# C6424_cslr_edmacc register map
Vendor: Texas Instruments
Peripheral module from a debugger description file.
Registers are 32-bit, read-write, reset 0x0 unless marked. A register's access mark holds for its fields unless they carry their own. Offsets are as the file gives them; lines under a group give offsets from that group; [hi:lo] are bit positions; {n}, {i} and the like mark numbered series; 'fields as' and 'values as' point back to an identical list; <NAME> marks a mode.

## EDMACC — Enhanced DMA Channel Controller Module.
0x00 REV ro reset 0x40015300 — Peripheral Revision
  [31:0] PID — Reserved
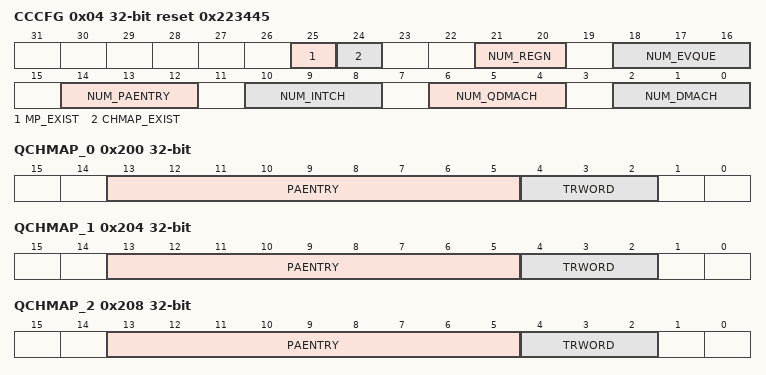
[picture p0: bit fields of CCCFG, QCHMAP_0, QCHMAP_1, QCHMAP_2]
0x04 CCCFG access not given reset 0x223445 — CC Configuration
  [25] MP_EXIST ro — Memory Protection Existence
    0=None (No Memory protection); 1=INCLUDED (Memory protection logic included)
  [24] CHMAP_EXIST ro — Channel Mapping Existence
    0=None (No Channel Mapping); 1=INCLUDED (Channel mapping logic included)
  [21:20] NUM_REGN ro — Number of MP and Shadow regions
    0=0 Regions; 1=2 Regions; 2=4 Regions; 3=8 Regions
  [18:16] NUM_EVQUE ro — Number of Queues/Number of TCs
    {v}={v+1} TC/Event Queue (v=0..7)
  [14:12] NUM_PAENTRY ro — Number of PaRAM entries
    0=16 Entries; 1=32 Entries; 2=64 Entries; 3=128 Entries; 4=256 Entries; 5=512 Entries
  [10:8] NUM_INTCH ro — Number of Interrupt Channels
    1=8 Interrupt Channels; 2=16 Interrupt Channels; 3=32 Interrupt Channels; 4=64 Interrupt Channels
  [6:4] NUM_QDMACH ro — Number of QDMA Channels
    0=NONE (No QDMA Channels); 1=2 QDMA Channels; 2=4 QDMA Channels; 3=6 QDMA Channels; 4=8 QDMA Channels
  [2:0] NUM_DMACH ro — Number of DMA Channels
    0=NONE (No DMA Channels); 1=4 DMA Channels; 2=8 DMA Channels; 3=16 DMA Channels; 4=32 DMA Channels; 5=64 DMA Channels
0x200 QCHMAP_0 access not given — QDMA Channel Mapping to PaRAM{QCHMAP}
  [13:5] PAENTRY rw — Points to the PaRAM Entry number for the DMA Channel N
  [4:2] TRWORD rw — Points to the specific trigger word of the PaRAM entry defined by PAENTRY
0x204 QCHMAP_1 access not given — QDMA Channel Mapping to PaRAM{QCHMAP}
  fields as QCHMAP_0
0x208 QCHMAP_2 access not given — QDMA Channel Mapping to PaRAM{QCHMAP}
  fields as QCHMAP_0
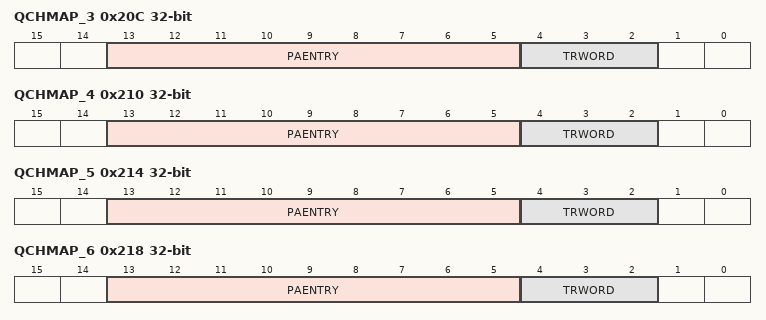
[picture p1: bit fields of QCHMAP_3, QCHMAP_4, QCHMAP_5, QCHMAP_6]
0x20C QCHMAP_3 access not given — QDMA Channel Mapping to PaRAM{QCHMAP}
  fields as QCHMAP_0
0x210 QCHMAP_4 access not given — QDMA Channel Mapping to PaRAM{QCHMAP}
  fields as QCHMAP_0
0x214 QCHMAP_5 access not given — QDMA Channel Mapping to PaRAM{QCHMAP}
  fields as QCHMAP_0
0x218 QCHMAP_6 access not given — QDMA Channel Mapping to PaRAM{QCHMAP}
  fields as QCHMAP_0
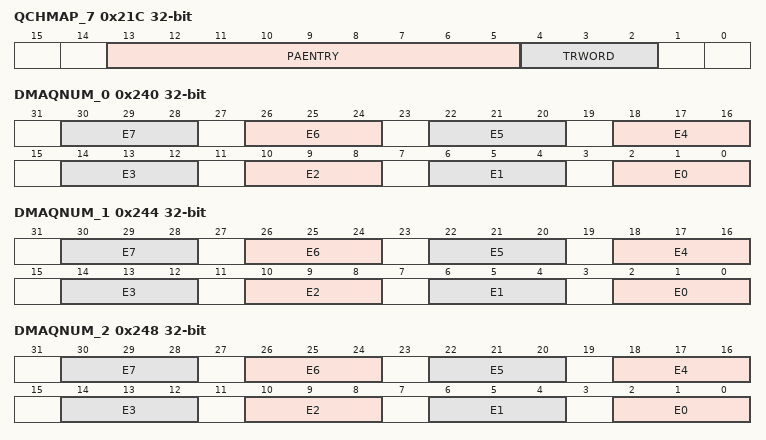
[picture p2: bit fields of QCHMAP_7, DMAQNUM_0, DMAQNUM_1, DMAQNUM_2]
0x21C QCHMAP_7 access not given — QDMA Channel Mapping to PaRAM{QCHMAP}
  fields as QCHMAP_0
0x240 DMAQNUM_0 access not given — DMA Queue Number{DMAQNUM}
  [4n+2:4n] E{n} rw (n=0..7) — Event number = (ArrayIndex * 8) + {n}
0x244 DMAQNUM_1 access not given — DMA Queue Number{DMAQNUM}
  [4n+2:4n] E{n} rw (n=0..7) — Event number = (ArrayIndex * 8) + {n}
0x248 DMAQNUM_2 access not given — DMA Queue Number{DMAQNUM}
  [4n+2:4n] E{n} rw (n=0..7) — Event number = (ArrayIndex * 8) + {n}
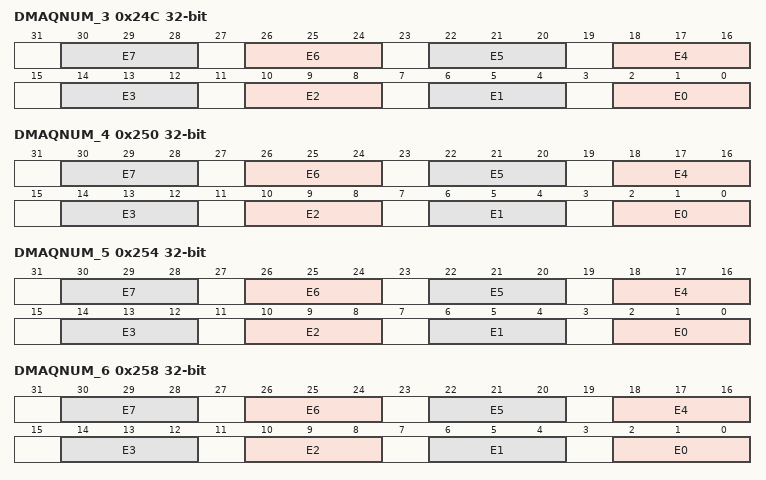
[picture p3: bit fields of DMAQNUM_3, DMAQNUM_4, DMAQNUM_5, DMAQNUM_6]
0x24C DMAQNUM_3 access not given — DMA Queue Number{DMAQNUM}
  [4n+2:4n] E{n} rw (n=0..7) — Event number = (ArrayIndex * 8) + {n}
0x250 DMAQNUM_4 access not given — DMA Queue Number{DMAQNUM}
  [4n+2:4n] E{n} rw (n=0..7) — Event number = (ArrayIndex * 8) + {n}
0x254 DMAQNUM_5 access not given — DMA Queue Number{DMAQNUM}
  [4n+2:4n] E{n} rw (n=0..7) — Event number = (ArrayIndex * 8) + {n}
0x258 DMAQNUM_6 access not given — DMA Queue Number{DMAQNUM}
  [4n+2:4n] E{n} rw (n=0..7) — Event number = (ArrayIndex * 8) + {n}
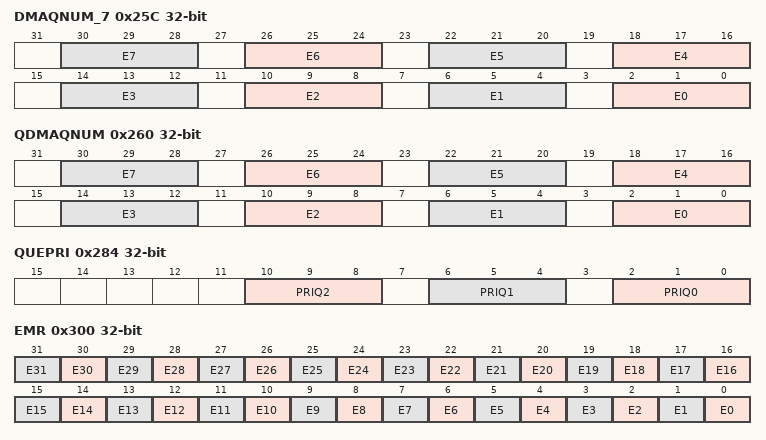
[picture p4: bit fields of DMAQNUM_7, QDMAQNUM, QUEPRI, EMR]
0x25C DMAQNUM_7 access not given — DMA Queue Number{DMAQNUM}
  [4n+2:4n] E{n} rw (n=0..7) — Event number = (ArrayIndex * 8) + {n}
0x260 QDMAQNUM access not given — QDMA Queue Number
  [4n+2:4n] E{n} rw (n=0..7) — Event number {n}
0x284 QUEPRI access not given — Queue Priority
  [10:8] PRIQ2 rw — Priority level for Queue 2
  [6:4] PRIQ1 rw — Priority level for Queue 1
  [2:0] PRIQ0 rw — Priority level for Queue 0
0x300 EMR ro — Event Miss Register
  [n] E{n} (n=0..31) — Event missed number {n}
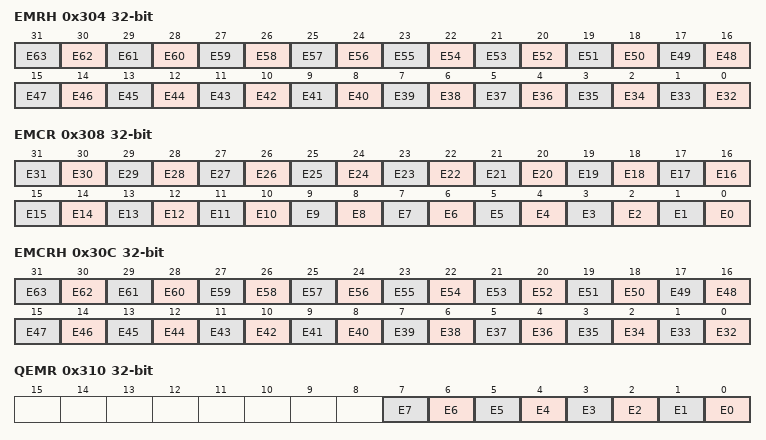
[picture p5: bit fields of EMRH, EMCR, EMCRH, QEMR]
0x304 EMRH ro — Event Miss Register High
  [n-32] E{n} (n=32..63) — Event missed number {n}
0x308 EMCR ro — Event Miss Clear Register
  [n] E{n} (n=0..31) — Event missed number {n}
0x30C EMCRH ro — Event Miss Clear Register High
  [n-32] E{n} (n=32..63) — Event missed number {n}
0x310 QEMR access not given — QDMA Event Miss Register
  [n] E{n} ro (n=0..7) — Event miss event {n}
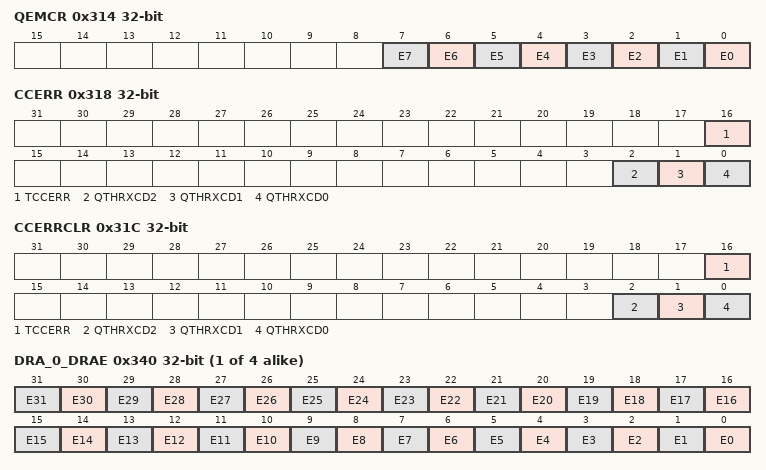
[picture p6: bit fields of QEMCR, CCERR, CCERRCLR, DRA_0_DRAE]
0x314 QEMCR access not given — QDMA Event Miss Register
  [n] E{n} wo (n=0..7) — Event miss event {n}
0x318 CCERR access not given — CC Error Register
  [16] TCCERR ro — Transfer completion code error
  [2] QTHRXCD2 ro — Queue Threshold Error for Queue 2
  [1] QTHRXCD1 ro — Queue Threshold Error for Queue 1
  [0] QTHRXCD0 ro — Queue Threshold Error for Queue 0
0x31C CCERRCLR access not given — CC Error Clear Register
  [16] TCCERR wo — Transfer completion code error
  [2] QTHRXCD2 wo — Queue Threshold Error for Queue 2
  [1] QTHRXCD1 wo — Queue Threshold Error for Queue 1
  [0] QTHRXCD0 wo — Queue Threshold Error for Queue 0
0x320 EEVAL access not given — Error Evaluation Register
  [0] EVAL wo — Error interrupt Evaluate
    1=EVAL (Error Interrupt Evaluate)
{0x340+8i} DRA_{i}_DRAE ro (i=0..3) — DMA Region Access Enable
  [n] E{n} (n=0..31) — Event missed number {n}
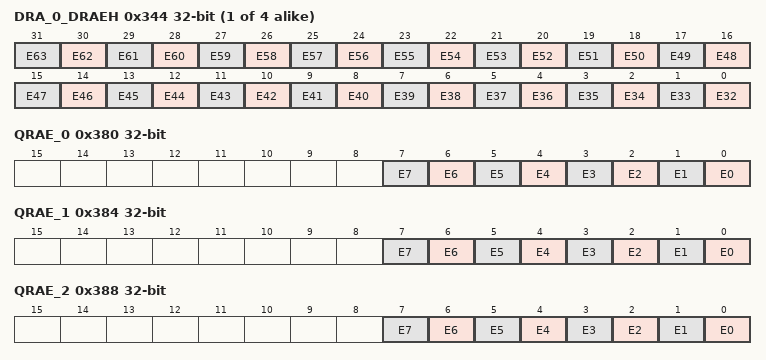
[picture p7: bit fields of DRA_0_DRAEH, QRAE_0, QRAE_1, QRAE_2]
{0x344+8i} DRA_{i}_DRAEH ro (i=0..3) — DMA Region Access Enable High
  [n-32] E{n} (n=32..63) — Event missed number {n}
0x380 QRAE_0 access not given — QDMA Region Access Enable{QRAE}
  [n] E{n} ro (n=0..7) — QDMA Register bit {n}
0x384 QRAE_1 access not given — QDMA Region Access Enable{QRAE}
  [n] E{n} ro (n=0..7) — QDMA Register bit {n}
0x388 QRAE_2 access not given — QDMA Region Access Enable{QRAE}
  [n] E{n} ro (n=0..7) — QDMA Register bit {n}
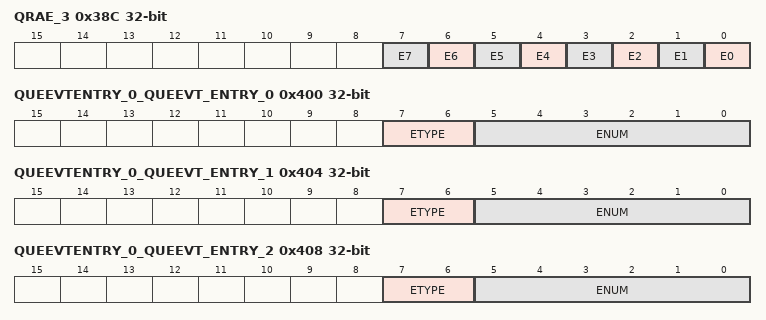
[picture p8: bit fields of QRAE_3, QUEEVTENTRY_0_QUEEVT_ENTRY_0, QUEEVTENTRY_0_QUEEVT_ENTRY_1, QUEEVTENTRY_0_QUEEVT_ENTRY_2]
0x38C QRAE_3 access not given — QDMA Region Access Enable{QRAE}
  [n] E{n} ro (n=0..7) — QDMA Register bit {n}
0x400 QUEEVTENTRY_0_QUEEVT_ENTRY_0 ro — Event Entry{EVT_ENTRY}
  [7:6] ETYPE — Event Source - ER/ESR/CER/QER
  [5:0] ENUM — Event
0x404 QUEEVTENTRY_0_QUEEVT_ENTRY_1 ro — Event Entry{EVT_ENTRY}
  [7:6] ETYPE — Event Source - ER/ESR/CER/QER
  [5:0] ENUM — Event
0x408 QUEEVTENTRY_0_QUEEVT_ENTRY_2 ro — Event Entry{EVT_ENTRY}
  [7:6] ETYPE — Event Source - ER/ESR/CER/QER
  [5:0] ENUM — Event
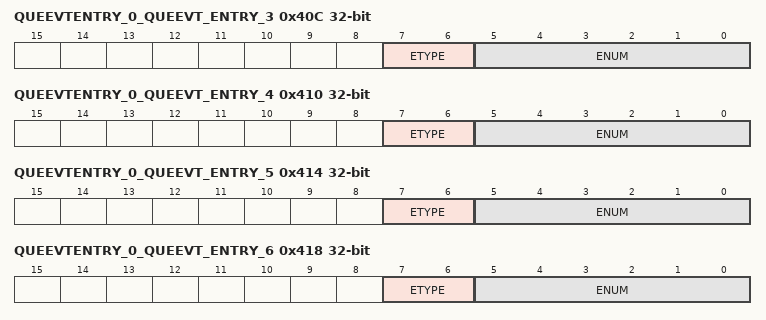
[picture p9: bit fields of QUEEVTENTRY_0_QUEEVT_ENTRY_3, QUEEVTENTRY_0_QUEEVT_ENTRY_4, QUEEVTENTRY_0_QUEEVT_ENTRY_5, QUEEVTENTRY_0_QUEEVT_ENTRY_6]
0x40C QUEEVTENTRY_0_QUEEVT_ENTRY_3 ro — Event Entry{EVT_ENTRY}
  [7:6] ETYPE — Event Source - ER/ESR/CER/QER
  [5:0] ENUM — Event
0x410 QUEEVTENTRY_0_QUEEVT_ENTRY_4 ro — Event Entry{EVT_ENTRY}
  [7:6] ETYPE — Event Source - ER/ESR/CER/QER
  [5:0] ENUM — Event
0x414 QUEEVTENTRY_0_QUEEVT_ENTRY_5 ro — Event Entry{EVT_ENTRY}
  [7:6] ETYPE — Event Source - ER/ESR/CER/QER
  [5:0] ENUM — Event
0x418 QUEEVTENTRY_0_QUEEVT_ENTRY_6 ro — Event Entry{EVT_ENTRY}
  [7:6] ETYPE — Event Source - ER/ESR/CER/QER
  [5:0] ENUM — Event
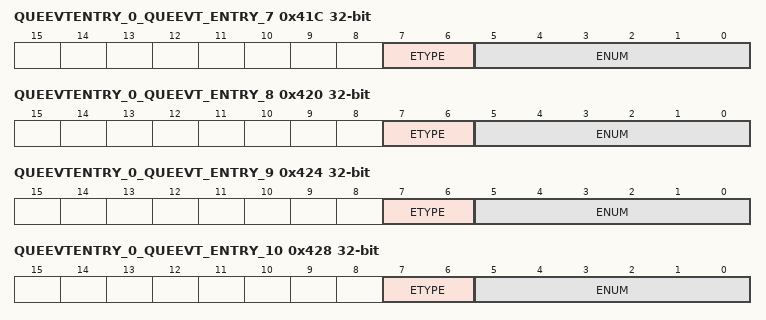
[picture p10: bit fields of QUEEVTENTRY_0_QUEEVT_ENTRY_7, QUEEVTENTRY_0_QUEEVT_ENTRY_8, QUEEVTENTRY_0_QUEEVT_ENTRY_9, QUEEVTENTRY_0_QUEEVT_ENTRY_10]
0x41C QUEEVTENTRY_0_QUEEVT_ENTRY_7 ro — Event Entry{EVT_ENTRY}
  [7:6] ETYPE — Event Source - ER/ESR/CER/QER
  [5:0] ENUM — Event
0x420 QUEEVTENTRY_0_QUEEVT_ENTRY_8 ro — Event Entry{EVT_ENTRY}
  [7:6] ETYPE — Event Source - ER/ESR/CER/QER
  [5:0] ENUM — Event
0x424 QUEEVTENTRY_0_QUEEVT_ENTRY_9 ro — Event Entry{EVT_ENTRY}
  [7:6] ETYPE — Event Source - ER/ESR/CER/QER
  [5:0] ENUM — Event
0x428 QUEEVTENTRY_0_QUEEVT_ENTRY_10 ro — Event Entry{EVT_ENTRY}
  [7:6] ETYPE — Event Source - ER/ESR/CER/QER
  [5:0] ENUM — Event
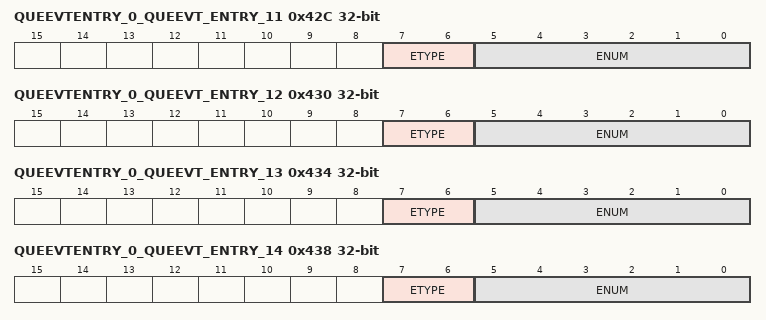
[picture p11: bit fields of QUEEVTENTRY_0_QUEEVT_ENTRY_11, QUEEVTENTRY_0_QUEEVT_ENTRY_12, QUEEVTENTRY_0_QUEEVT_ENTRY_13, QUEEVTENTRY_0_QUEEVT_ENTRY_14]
0x42C QUEEVTENTRY_0_QUEEVT_ENTRY_11 ro — Event Entry{EVT_ENTRY}
  [7:6] ETYPE — Event Source - ER/ESR/CER/QER
  [5:0] ENUM — Event
0x430 QUEEVTENTRY_0_QUEEVT_ENTRY_12 ro — Event Entry{EVT_ENTRY}
  [7:6] ETYPE — Event Source - ER/ESR/CER/QER
  [5:0] ENUM — Event
0x434 QUEEVTENTRY_0_QUEEVT_ENTRY_13 ro — Event Entry{EVT_ENTRY}
  [7:6] ETYPE — Event Source - ER/ESR/CER/QER
  [5:0] ENUM — Event
0x438 QUEEVTENTRY_0_QUEEVT_ENTRY_14 ro — Event Entry{EVT_ENTRY}
  [7:6] ETYPE — Event Source - ER/ESR/CER/QER
  [5:0] ENUM — Event
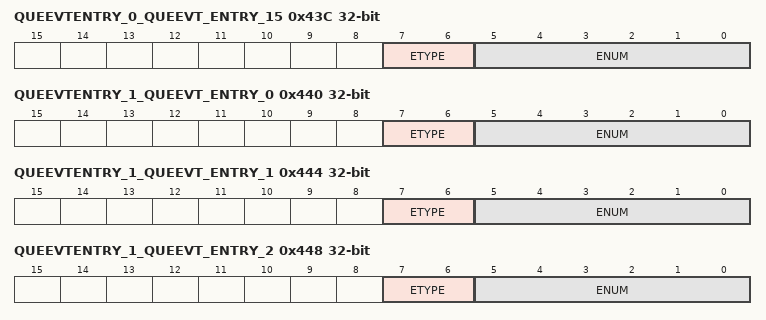
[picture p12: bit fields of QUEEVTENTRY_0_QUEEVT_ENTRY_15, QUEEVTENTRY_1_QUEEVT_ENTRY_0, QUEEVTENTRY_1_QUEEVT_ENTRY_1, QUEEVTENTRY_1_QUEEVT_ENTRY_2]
0x43C QUEEVTENTRY_0_QUEEVT_ENTRY_15 ro — Event Entry{EVT_ENTRY}
  [7:6] ETYPE — Event Source - ER/ESR/CER/QER
  [5:0] ENUM — Event
0x440 QUEEVTENTRY_1_QUEEVT_ENTRY_0 ro — Event Entry{EVT_ENTRY}
  [7:6] ETYPE — Event Source - ER/ESR/CER/QER
  [5:0] ENUM — Event
0x444 QUEEVTENTRY_1_QUEEVT_ENTRY_1 ro — Event Entry{EVT_ENTRY}
  [7:6] ETYPE — Event Source - ER/ESR/CER/QER
  [5:0] ENUM — Event
0x448 QUEEVTENTRY_1_QUEEVT_ENTRY_2 ro — Event Entry{EVT_ENTRY}
  [7:6] ETYPE — Event Source - ER/ESR/CER/QER
  [5:0] ENUM — Event
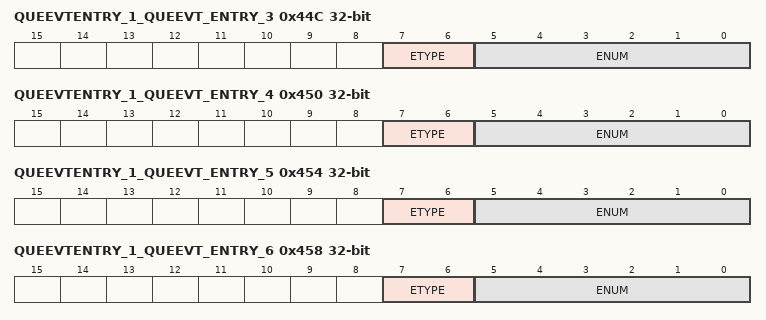
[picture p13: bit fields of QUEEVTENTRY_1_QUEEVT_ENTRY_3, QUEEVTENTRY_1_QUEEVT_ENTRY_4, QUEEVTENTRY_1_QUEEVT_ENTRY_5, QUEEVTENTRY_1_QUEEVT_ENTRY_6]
0x44C QUEEVTENTRY_1_QUEEVT_ENTRY_3 ro — Event Entry{EVT_ENTRY}
  [7:6] ETYPE — Event Source - ER/ESR/CER/QER
  [5:0] ENUM — Event
0x450 QUEEVTENTRY_1_QUEEVT_ENTRY_4 ro — Event Entry{EVT_ENTRY}
  [7:6] ETYPE — Event Source - ER/ESR/CER/QER
  [5:0] ENUM — Event
0x454 QUEEVTENTRY_1_QUEEVT_ENTRY_5 ro — Event Entry{EVT_ENTRY}
  [7:6] ETYPE — Event Source - ER/ESR/CER/QER
  [5:0] ENUM — Event
0x458 QUEEVTENTRY_1_QUEEVT_ENTRY_6 ro — Event Entry{EVT_ENTRY}
  [7:6] ETYPE — Event Source - ER/ESR/CER/QER
  [5:0] ENUM — Event
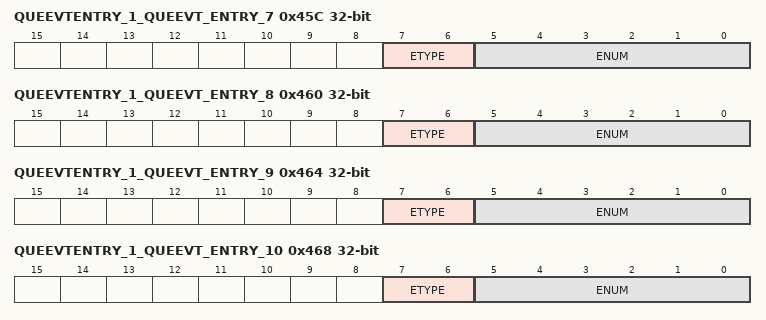
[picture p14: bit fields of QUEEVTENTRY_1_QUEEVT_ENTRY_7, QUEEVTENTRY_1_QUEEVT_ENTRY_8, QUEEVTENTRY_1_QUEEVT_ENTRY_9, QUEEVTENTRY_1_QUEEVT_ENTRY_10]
0x45C QUEEVTENTRY_1_QUEEVT_ENTRY_7 ro — Event Entry{EVT_ENTRY}
  [7:6] ETYPE — Event Source - ER/ESR/CER/QER
  [5:0] ENUM — Event
0x460 QUEEVTENTRY_1_QUEEVT_ENTRY_8 ro — Event Entry{EVT_ENTRY}
  [7:6] ETYPE — Event Source - ER/ESR/CER/QER
  [5:0] ENUM — Event
0x464 QUEEVTENTRY_1_QUEEVT_ENTRY_9 ro — Event Entry{EVT_ENTRY}
  [7:6] ETYPE — Event Source - ER/ESR/CER/QER
  [5:0] ENUM — Event
0x468 QUEEVTENTRY_1_QUEEVT_ENTRY_10 ro — Event Entry{EVT_ENTRY}
  [7:6] ETYPE — Event Source - ER/ESR/CER/QER
  [5:0] ENUM — Event
0x46C QUEEVTENTRY_1_QUEEVT_ENTRY_11 ro — Event Entry{EVT_ENTRY}
  [7:6] ETYPE — Event Source - ER/ESR/CER/QER
  [5:0] ENUM — Event
0x470 QUEEVTENTRY_1_QUEEVT_ENTRY_12 ro — Event Entry{EVT_ENTRY}
  [7:6] ETYPE — Event Source - ER/ESR/CER/QER
  [5:0] ENUM — Event
0x474 QUEEVTENTRY_1_QUEEVT_ENTRY_13 ro — Event Entry{EVT_ENTRY}
  [7:6] ETYPE — Event Source - ER/ESR/CER/QER
  [5:0] ENUM — Event
0x478 QUEEVTENTRY_1_QUEEVT_ENTRY_14 ro — Event Entry{EVT_ENTRY}
  [7:6] ETYPE — Event Source - ER/ESR/CER/QER
  [5:0] ENUM — Event
0x47C QUEEVTENTRY_1_QUEEVT_ENTRY_15 ro — Event Entry{EVT_ENTRY}
  [7:6] ETYPE — Event Source - ER/ESR/CER/QER
  [5:0] ENUM — Event
0x480 QUEEVTENTRY_2_QUEEVT_ENTRY_0 ro — Event Entry{EVT_ENTRY}
  [7:6] ETYPE — Event Source - ER/ESR/CER/QER
  [5:0] ENUM — Event
0x484 QUEEVTENTRY_2_QUEEVT_ENTRY_1 ro — Event Entry{EVT_ENTRY}
  [7:6] ETYPE — Event Source - ER/ESR/CER/QER
  [5:0] ENUM — Event
0x488 QUEEVTENTRY_2_QUEEVT_ENTRY_2 ro — Event Entry{EVT_ENTRY}
  [7:6] ETYPE — Event Source - ER/ESR/CER/QER
  [5:0] ENUM — Event
0x48C QUEEVTENTRY_2_QUEEVT_ENTRY_3 ro — Event Entry{EVT_ENTRY}
  [7:6] ETYPE — Event Source - ER/ESR/CER/QER
  [5:0] ENUM — Event
0x490 QUEEVTENTRY_2_QUEEVT_ENTRY_4 ro — Event Entry{EVT_ENTRY}
  [7:6] ETYPE — Event Source - ER/ESR/CER/QER
  [5:0] ENUM — Event
0x494 QUEEVTENTRY_2_QUEEVT_ENTRY_5 ro — Event Entry{EVT_ENTRY}
  [7:6] ETYPE — Event Source - ER/ESR/CER/QER
  [5:0] ENUM — Event
0x498 QUEEVTENTRY_2_QUEEVT_ENTRY_6 ro — Event Entry{EVT_ENTRY}
  [7:6] ETYPE — Event Source - ER/ESR/CER/QER
  [5:0] ENUM — Event
0x49C QUEEVTENTRY_2_QUEEVT_ENTRY_7 ro — Event Entry{EVT_ENTRY}
  [7:6] ETYPE — Event Source - ER/ESR/CER/QER
  [5:0] ENUM — Event
0x4A0 QUEEVTENTRY_2_QUEEVT_ENTRY_8 ro — Event Entry{EVT_ENTRY}
  [7:6] ETYPE — Event Source - ER/ESR/CER/QER
  [5:0] ENUM — Event
0x4A4 QUEEVTENTRY_2_QUEEVT_ENTRY_9 ro — Event Entry{EVT_ENTRY}
  [7:6] ETYPE — Event Source - ER/ESR/CER/QER
  [5:0] ENUM — Event
0x4A8 QUEEVTENTRY_2_QUEEVT_ENTRY_10 ro — Event Entry{EVT_ENTRY}
  [7:6] ETYPE — Event Source - ER/ESR/CER/QER
  [5:0] ENUM — Event
0x4AC QUEEVTENTRY_2_QUEEVT_ENTRY_11 ro — Event Entry{EVT_ENTRY}
  [7:6] ETYPE — Event Source - ER/ESR/CER/QER
  [5:0] ENUM — Event
0x4B0 QUEEVTENTRY_2_QUEEVT_ENTRY_12 ro — Event Entry{EVT_ENTRY}
  [7:6] ETYPE — Event Source - ER/ESR/CER/QER
  [5:0] ENUM — Event
0x4B4 QUEEVTENTRY_2_QUEEVT_ENTRY_13 ro — Event Entry{EVT_ENTRY}
  [7:6] ETYPE — Event Source - ER/ESR/CER/QER
  [5:0] ENUM — Event
0x4B8 QUEEVTENTRY_2_QUEEVT_ENTRY_14 ro — Event Entry{EVT_ENTRY}
  [7:6] ETYPE — Event Source - ER/ESR/CER/QER
  [5:0] ENUM — Event
0x4BC QUEEVTENTRY_2_QUEEVT_ENTRY_15 ro — Event Entry{EVT_ENTRY}
  [7:6] ETYPE — Event Source - ER/ESR/CER/QER
  [5:0] ENUM — Event
0x600 QSTAT_0 access not given — Queue Status{QSTAT}
  [24] THRXD ro — Threshold Exceeded
  [22:21] Reserved — (access N)
  [20:16] WM ro — Watermark for Maximum Queue Usage
  [12:8] NUMVAL ro — Number of Valid Entries in Queue
  [3:0] STRTPTR ro — Start Pointer
0x604 QSTAT_1 access not given — Queue Status{QSTAT}
  fields as QSTAT_0
0x608 QSTAT_2 access not given — Queue Status{QSTAT}
  fields as QSTAT_0
0x620 QWMTHRA access not given reset 0x101010 — Queue Threshold A
  [20:16] Q2 rw — Q2 Threshold
  [12:8] Q1 rw — Q1 Threshold
  [4:0] Q0 rw — Q0 Threshold
0x640 CCSTAT access not given — Channel Controller Status
  [18] QUEACTV2 ro — Queue 2 Active
    0=NONE; 1=ACTIVE
  [17] QUEACTV1 ro — Queue 1 Active
    0=NONE; 1=ACTIVE
  [16] QUEACTV0 ro — Queue 0 Active
    0=NONE; 1=ACTIVE
  [13:8] COMPACT ro — Completion Request Active
    0=NONE
  [7:5] _RESV_7 — (access N)
  [4] ACTV ro — Channel Controller Active
    0=IDLE; 1=BUSY
  [3] _RESV_9 — (access N)
  [2] TRACTV ro — Transfer Request Active
    0=NONE; 1=ACTIVE
  [1] QEVTACTV ro — QDMA Event Active
    0=NONE; 1=ACTIVE
  [0] EVTACTV ro — DMA Event Active
    0=NONE; 1=ACTIVE
0x1000 ER ro — Event Register
  [n] E{n} (n=0..31) — Event {n}
0x1004 ERH ro — Event Register High
  [n-32] E{n} (n=32..63) — Event {n}
0x1008 ECR wo — Event Clear Register
  [all] fields
    1=CLEAR
  [n] E{n} (n=0..31) — Event {n}
0x100C ECRH wo — Event Clear Register High
  [all] fields
    1=CLEAR
  [n-32] E{n} (n=32..63) — Event {n}
0x1010 ESR wo — Event Set Register
  [all] fields
    1=SET
  [n] E{n} (n=0..31) — Event {n}
0x1014 ESRH wo — Event Set Register High
  [all] fields
    1=SET
  [n-32] E{n} (n=32..63) — Event {n}
0x1018 CER ro — Chained Event Register
  [n] E{n} (n=0..31) — Event {n}
0x101C CERH ro — Chained Event Register High
  [n-32] E{n} (n=32..63) — Event {n}
0x1020 EER ro — Event Enable Register
  [31] E31 — Event 31
    1=?
  [n] E{n} (n=0..30) — Event {n}
0x1024 EERH ro — Event Enable Register High
  [n-32] E{n} (n=32..63) — Event {n}
0x1028 EECR wo — Event Enable Clear Register
  [all] fields
    1=CLEAR
  [n] E{n} (n=0..31) — Event {n}
0x102C EECRH wo — Event Enable Clear Register High
  [all] fields
    1=CLEAR
  [n-32] E{n} (n=32..63) — Event {n}
0x1030 EESR wo — Event Enable Set Register
  [all] fields
    1=SET
  [n] E{n} (n=0..31) — Event {n}
0x1034 EESRH wo — Event Enable Set Register High
  [all] fields
    1=SET
  [n-32] E{n} (n=32..63) — Event {n}
0x1038 SER ro — Secondary Event Register
  [n] E{n} (n=0..31) — Event {n}
0x103C SERH ro — Secondary Event Register High
  [n-32] E{n} (n=32..63) — Event {n}
0x1040 SECR wo — Secondary Event Clear Register
  [all] fields
    1=CLEAR
  [n] E{n} (n=0..31) — Event {n}
0x1044 SECRH wo — Secondary Event Clear Register High
  [all] fields
    1=CLEAR
  [n-32] E{n} (n=32..63) — Event {n}
0x1050 IER ro — Interrupt Enable Register
  [n] I{n} (n=0..31) — Interrupt {n}
0x1054 IERH ro — Interrupt Enable Register High
  [n-32] I{n} (n=32..63) — Interrupt {n}
0x1058 IECR wo — Interrupt Enable Clear Register
  [all] fields
    1=CLEAR
  [n] I{n} (n=0..31) — Interrupt {n}
0x105C IECRH wo — Interrupt Enable Clear Register High
  [all] fields
    1=CLEAR
  [n-32] I{n} (n=32..63) — Interrupt {n}
0x1060 IESR wo — Interrupt Enable Set Register
  [all] fields
    1=SET
  [n] I{n} (n=0..31) — Interrupt {n}
0x1064 IESRH wo — Interrupt Enable Set Register High
  [all] fields
    1=SET
  [n-32] I{n} (n=32..63) — Interrupt {n}
0x1068 IPR ro — Interrupt Pending Register
  [n] I{n} (n=0..31) — Interrupt {n}
0x106C IPRH ro — Interrupt Pending Register High
  [n-32] I{n} (n=32..63) — Interrupt {n}
0x1070 ICR wo — Interrupt Clear Register
  [all] fields
    1=CLEAR
  [n] I{n} (n=0..31) — Interrupt {n}
0x1074 ICRH wo — Interrupt Clear Register High
  [all] fields
    1=CLEAR
  [n-32] I{n} (n=32..63) — Interrupt {n}
0x1078 IEVAL access not given — Interrupt Clear Register High
  [0] EVAL wo — Interrupt Evaluate
    1=EVAL (Causes tpcc_intN output to be pulsed is any enabled IERn and IPRn pending)
0x1080 QER access not given — QDMA Event Register
  [n] E{n} ro (n=0..7) — Event {n}
0x1084 QEER access not given — QDMA Event Enable Register
  [n] E{n} ro (n=0..7) — Event {n}
0x1088 QEECR access not given — QDMA Event Enable Clear Register
  [all] fields
    1=CLEAR
  [n] E{n} ro (n=0..7) — Event {n}
0x108C QEESR access not given — QDMA Event Enable Set Register
  [all] fields
    1=SET
  [n] E{n} ro (n=0..7) — Event {n}
0x1090 QSER access not given — QDMA Secondary Event Register
  [n] E{n} ro (n=0..7) — Event {n}
0x1094 QSECR access not given — QDMA Secondary Event Clear Register
  [all] fields
    1=CLEAR
  [n] E{n} ro (n=0..7) — Event {n}
{0x2000+0x200*i} SHADOW_{i}_ER access not given (i=0..3) — Event Register
  [31:0] REG
{0x2004+0x200*i} SHADOW_{i}_ERH access not given (i=0..3) — Event Register High
  [31:0] REG
{0x2008+0x200*i} SHADOW_{i}_ECR access not given (i=0..3) — Event Clear Register
  [31:0] REG
{0x200C+0x200*i} SHADOW_{i}_ECRH access not given (i=0..3) — Event Clear Register High
  [31:0] REG
{0x2010+0x200*i} SHADOW_{i}_ESR access not given (i=0..3) — Event Set Register
  [31:0] REG
{0x2014+0x200*i} SHADOW_{i}_ESRH access not given (i=0..3) — Event Set Register High
  [31:0] REG
{0x2018+0x200*i} SHADOW_{i}_CER access not given (i=0..3) — Chained Event Register
  [31:0] REG
{0x201C+0x200*i} SHADOW_{i}_CERH access not given (i=0..3) — Chained Event Register High
  [31:0] REG
{0x2020+0x200*i} SHADOW_{i}_EER access not given (i=0..3) — Event Enable Register
  [31:0] REG
{0x2024+0x200*i} SHADOW_{i}_EERH access not given (i=0..3) — Event Enable Register High
  [31:0] REG
{0x2028+0x200*i} SHADOW_{i}_EECR access not given (i=0..3) — Event Enable Clear Register
  [31:0] REG
{0x202C+0x200*i} SHADOW_{i}_EECRH access not given (i=0..3) — Event Enable Clear Register High
  [31:0] REG
{0x2030+0x200*i} SHADOW_{i}_EESR access not given (i=0..3) — Event Enable Set Register
  [31:0] REG
{0x2034+0x200*i} SHADOW_{i}_EESRH access not given (i=0..3) — Event Enable Set Register High
  [31:0] REG
{0x2038+0x200*i} SHADOW_{i}_SER access not given (i=0..3) — Secondary Event Register
  [31:0] REG
{0x203C+0x200*i} SHADOW_{i}_SERH access not given (i=0..3) — Secondary Event Register High
  [31:0] REG
{0x2040+0x200*i} SHADOW_{i}_SECR access not given (i=0..3) — Secondary Event Clear Register
  [31:0] REG
{0x2044+0x200*i} SHADOW_{i}_SECRH access not given (i=0..3) — Secondary Event Clear Register High
  [31:0] REG
{0x2050+0x200*i} SHADOW_{i}_IER access not given (i=0..3) — Interrupt Enable Register
  [31:0] REG
{0x2054+0x200*i} SHADOW_{i}_IERH access not given (i=0..3) — Interrupt Enable Register High
  [31:0] REG
{0x2058+0x200*i} SHADOW_{i}_IECR access not given (i=0..3) — Interrupt Enable Clear Register
  [31:0] REG
{0x205C+0x200*i} SHADOW_{i}_IECRH access not given (i=0..3) — Interrupt Enable Clear Register High
  [31:0] REG
{0x2060+0x200*i} SHADOW_{i}_IESR access not given (i=0..3) — Interrupt Enable Set Register
  [31:0] REG
{0x2064+0x200*i} SHADOW_{i}_IESRH access not given (i=0..3) — Interrupt Enable Set Register High
  [31:0] REG
{0x2068+0x200*i} SHADOW_{i}_IPR access not given (i=0..3) — Interrupt Pending Register
  [31:0] REG
{0x206C+0x200*i} SHADOW_{i}_IPRH access not given (i=0..3) — Interrupt Pending Register High
  [31:0] REG
{0x2070+0x200*i} SHADOW_{i}_ICR access not given (i=0..3) — Interrupt Clear Register
  [31:0] REG
{0x2074+0x200*i} SHADOW_{i}_ICRH access not given (i=0..3) — Interrupt Clear Register High
  [31:0] REG
{0x2078+0x200*i} SHADOW_{i}_IEVAL access not given (i=0..3) — Interrupt Clear Register High
  [31:0] REG
{0x2080+0x200*i} SHADOW_{i}_QER access not given (i=0..3) — QDMA Event Register
  [31:0] REG
{0x2084+0x200*i} SHADOW_{i}_QEER access not given (i=0..3) — QDMA Event Enable Register
  [31:0] REG
{0x2088+0x200*i} SHADOW_{i}_QEECR access not given (i=0..3) — QDMA Event Enable Clear Register
  [31:0] REG
{0x208C+0x200*i} SHADOW_{i}_QEESR access not given (i=0..3) — QDMA Event Enable Set Register
  [31:0] REG
{0x2090+0x200*i} SHADOW_{i}_QSER access not given (i=0..3) — QDMA Secondary Event Register
  [31:0] REG
{0x2094+0x200*i} SHADOW_{i}_QSECR access not given (i=0..3) — QDMA Secondary Event Clear Register
  [31:0] REG
{0x4000+0x20*i} PARAMENTRY_{i}_OPT access not given (i=0..127) — Option
  [27:24] PRIVID ro — Privilege ID for external host/cpu/dma
  [23] ITCCHEN rw — Intermediate transfer completion chaining enable
    0=DISABLE (ITCC Disabled); 1=ENABLE (ITCC Enabled)
  [22] TCCHEN rw — Transfer completion chaining enable
    0=DISABLE (TCC Disabled); 1=ENABLE (TCC Enabled)
  [21] ITCINTEN rw — Intermediate transfer completion interrupt enable
    0=DISABLE; 1=ENABLE
  [20] TCINTEN rw — Transfer completion interrupt enable
    0=DISABLE; 1=ENABLE
  [17:12] TCC rw — Transfer completion code
  [11] TCCMODE rw — Transfer completion mode
    0=NORMAL; 1=EARLY
  [10:8] FWID rw — Fifo Width
    0=8; 1=16; 2=32; 3=64; 4=128; 5=256
  [3] STATIC rw — Static entry
    0=NORMAL; 1=STATIC
  [2] SYNCDIM rw — Transfer Synchronization Dimension
    0=ASYNC; 1=ABSYNC
  [1] DAM rw — Destination address mode
    0=INCR; 1=CONST
  [0] SAM rw — Source address mode
    0=INCR; 1=CONST
{0x4004+0x20*i} PARAMENTRY_{i}_SRC (i=0..127) — Source Address
{0x4008+0x20*i} PARAMENTRY_{i}_A_B_CNT (i=0..127) — A Count
  [31:16] BCNT — B Count
  [15:0] ACNT — A Count
{0x400C+0x20*i} PARAMENTRY_{i}_DST (i=0..127) — Destination Address
{0x4010+0x20*i} PARAMENTRY_{i}_SRC_DST_BIDX (i=0..127) — SRC B Index, DST B Index
  [31:16] DSTBIDX — Destination B Index
  [15:0] SRCBIDX — Source B Index
{0x4014+0x20*i} PARAMENTRY_{i}_LINK_BCNTRLD (i=0..127) — Link Address
  [31:16] BCNTRLD — B Count Reload
  [15:0] LINK — Link Address
{0x4018+0x20*i} PARAMENTRY_{i}_SRC_DST_CIDX (i=0..127) — Source C Index
  [31:16] DSTCIDX — Destination C Index
  [15:0] SRCCIDX — Source C Index
{0x401C+0x20*i} PARAMENTRY_{i}_CCNT access not given (i=0..127) — C Count
  [15:0] CCNT rw — C Counter
